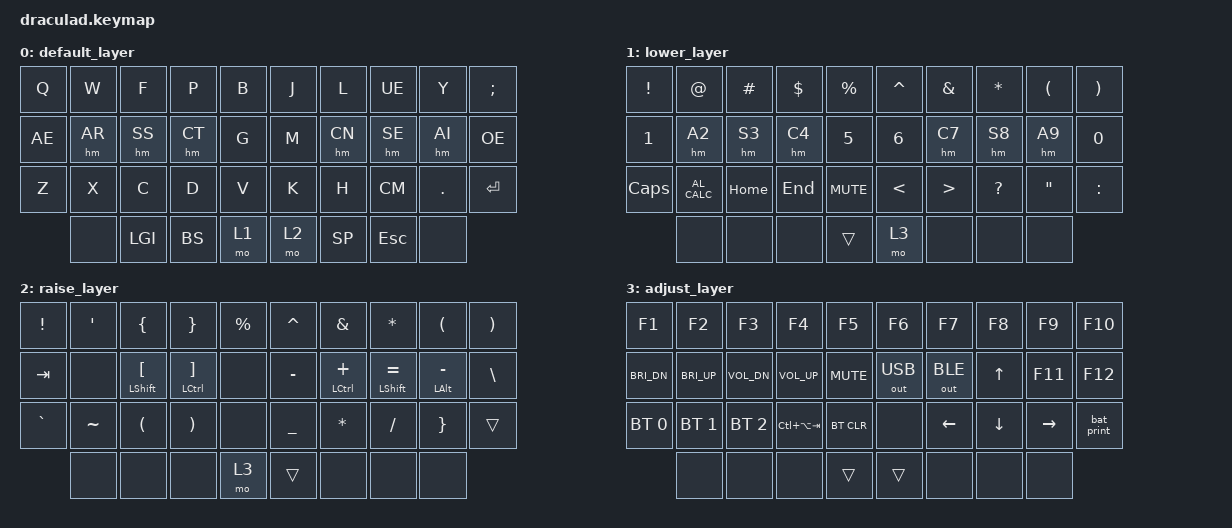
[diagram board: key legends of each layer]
#include <behaviors.dtsi>
#include <dt-bindings/zmk/keys.h>
#include <dt-bindings/zmk/bt.h>
#include <dt-bindings/zmk/ext_power.h>
#include <dt-bindings/zmk/outputs.h>
#include <behaviors/bat_print.dtsi>

#define B0 BT_SEL 0
#define B1 BT_SEL 1
#define B2 BT_SEL 2
#define BC BT_CLR

#define AR LALT R
#define SS LSHFT S
#define CT LCTRL T

#define A2 LALT N2
#define S3 LSHFT N3
#define C4 LCTRL N4

#define AI RALT I
#define SE RSHFT E
#define CN RCTRL N

#define A9 RALT N9
#define S8 RSHFT N8
#define C7 RCTRL N7

#define LGI LGUI
#define BS BSPC
#define CM COMMA
#define SP SPACE

/ {

        behaviors {
        hm: homerow_mod {
            compatible = "zmk,behavior-hold-tap";
            label = "HOMEROW_MOD";
            #binding-cells = <2>;
            tapping-term-ms = <250>;
            quick-tap-ms = <150>;
            flavor = "balanced";
            bindings = <&kp>, <&kp>;
        };
        AE: AE {
            compatible = "zmk,behavior-mod-morph";
            #binding-cells = <0>;
            bindings = <&kp A>, <&kp RA(Q)>;
            mods = <(MOD_RALT)>;
        };
        OE: OE {
            compatible = "zmk,behavior-mod-morph";
            #binding-cells = <0>;
            bindings = <&kp O>, <&kp RA(P)>;
            mods = <(MOD_LALT)>;
        };
        UE: UE {
            compatible = "zmk,behavior-mod-morph";
            #binding-cells = <0>;
            bindings = <&kp U>, <&kp RA(Y)>;
            mods = <(MOD_LALT)>;
        };
        SZ: SZ {
            compatible = "zmk,behavior-mod-morph";
            #binding-cells = <0>;
            bindings = <&kp S>, <&kp RA(S)>;
            mods = <(MOD_LALT)>;
        };
        };
keymap {
compatible = "zmk,keymap";

default_layer {
// -------------------------------------------------------------------
// |  Q  |  W  |  F  |  P  |  B  |   |  J  |  L  | U/Ü |  Y  |  ;  |
// | A/Ä |  R  |  S  |  T  |  G  |   |  M  |  N  |  E  |  I  | O/Ö |
// |  Z  |  X  |  C  |  D  |  V  |   |  K  |  H  |  ,  |  .  | ENT |
//       |     | GUI | BSPC| LWR |   | RSE | SPC | ESC |     |
bindings = <
 &kp Q   &kp W   &kp F   &kp P   &kp B     &kp J   &kp L   &UE     &kp Y   &kp SEMI    
 &AE     &hm AR  &hm SS  &hm CT  &kp G     &kp M   &hm CN  &hm SE  &hm AI  &OE 
 &kp Z   &kp X   &kp C   &kp D   &kp V     &kp K   &kp H   &kp CM  &kp DOT &kp RET 
         &none   &kp LGI &kp BS  &mo 1     &mo 2   &kp SP  &kp ESC &none
>;
};

lower_layer {
// -------------------------------------------------------------------
// |  !  |  @  |  #  |  $  |  %  |   |  ^  |  &  |  *  |  (  |  )  |
// |  1  |  2  |  3  |  4  |  5  |   |  6  |  7  |  8  |  9  |  0  |
// | CAPS| CALC| HOME| END | MUTE|   |  <  |  >  |  ?  |  "  |  :  |
//       |     |     |     |     |   | ADJ |     |     |     |
bindings = <
&kp EXCL  &kp AT         &kp HASH  &kp DLLR  &kp PRCNT   &kp CARET  &kp AMPS  &kp ASTRK  &kp LPAR  &kp RPAR
&kp N1    &hm A2         &hm S3    &hm C4    &kp N5      &kp N6     &hm C7    &hm S8     &hm A9    &kp N0
&kp CAPS  &kp C_AL_CALC  &kp HOME  &kp END   &kp C_MUTE  &kp LT     &kp GT    &kp QMARK  &kp DQT   &kp COLON
          &none          &none     &none     &trans      &mo 3      &none     &none      &none
>;
};


raise_layer {
// -------------------------------------------------------------------
// |  !  |  '  |  {  |  }  |  %  |   |  ^  |  &  |  *  |  (  |  )  |
// | TAB |     |  [  |  ]  |     |   |  -  |  +  |  =  |  -  |  \  |
// |  `  |  ~  |  (  |  )  |     |   |  _  |  *  |  /  |  }  | ENT |
//       |     |     |     | ADJ |   |     |     |     |     |
                        bindings = <
&kp EXCL   &kp SQT    &kp LBRC        &kp RBRC        &kp PRCNT      &kp CARET  &kp AMPS        &kp ASTRK        &kp LPAR        &kp RPAR
&kp TAB    &none      &hm LSHFT LBKT  &hm LCTRL RBKT  &none          &kp MINUS  &hm LCTRL PLUS  &hm LSHFT EQUAL  &hm LALT MINUS  &kp BSLH
&kp GRAVE  &kp TILDE  &kp LPAR        &kp RPAR        &none          &kp UNDER  &kp ASTRK       &kp FSLH         &kp RBRC        &trans
           &none      &none           &none           &mo 3          &trans     &none           &none            &none 
>;
};

adjust_layer {
// -------------------------------------------------------------------
// |  F1 |  F2 |  F3 |  F4 |  F5 |   |  F6 |  F7 |  F8 |  F9 | F10 |
// | BRI-| BRI+| VOL-| VOL+| MUTE|   | USB | BLE |  UP | F11 | F12 |
// | BT0 | BT1 | BT2 | TASK| BTCL|   |     | LFT | DWN | RGT | BAT |
//       |     |     |     |     |   |     |     |     |     |
                        bindings = <
&kp F1        &kp F2        &kp F3        &kp F4           &kp F5      &kp F6  &kp F7    &kp F8    &kp F9     &kp F10
&kp C_BRI_DN  &kp C_BRI_UP  &kp C_VOL_DN  &kp C_VOL_UP     &kp C_MUTE  &out OUT_USB  &out OUT_BLE  &kp UP    &kp F11    &kp F12
&bt BT_SEL 0  &bt BT_SEL 1  &bt BT_SEL 2  &kp LC(LA(TAB))  &bt BT_CLR  &none   &kp LEFT  &kp DOWN  &kp RIGHT  &bat_print
              &none         &none         &none            &trans      &trans  &none     &none     &none
>;
};
};
};
